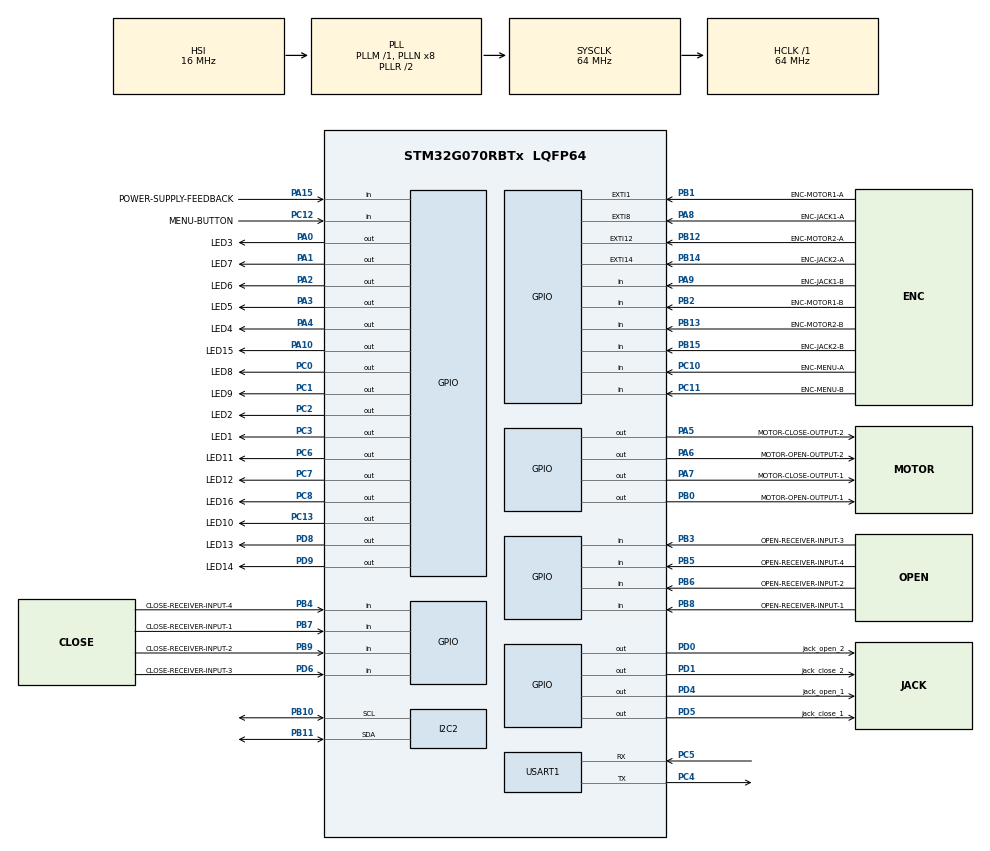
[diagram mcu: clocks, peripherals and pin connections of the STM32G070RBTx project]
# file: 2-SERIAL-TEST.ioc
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Dma.Request0=USART1_TX
Dma.USART1_TX.0.Direction=DMA_MEMORY_TO_PERIPH
Dma.USART1_TX.0.EventEnable=DISABLE
Dma.USART1_TX.0.Instance=DMA1_Channel1
Dma.USART1_TX.0.MemDataAlignment=DMA_MDATAALIGN_BYTE
Dma.USART1_TX.0.MemInc=DMA_MINC_ENABLE
Dma.USART1_TX.0.Mode=DMA_NORMAL
Dma.USART1_TX.0.PeriphDataAlignment=DMA_PDATAALIGN_BYTE
Dma.USART1_TX.0.PeriphInc=DMA_PINC_DISABLE
Dma.USART1_TX.0.Polarity=HAL_DMAMUX_REQ_GEN_RISING
Dma.USART1_TX.0.Priority=DMA_PRIORITY_HIGH
Dma.USART1_TX.0.RequestNumber=1
Dma.USART1_TX.0.SignalID=NONE
Dma.USART1_TX.0.SyncEnable=DISABLE
Dma.USART1_TX.0.SyncPolarity=HAL_DMAMUX_SYNC_NO_EVENT
Dma.USART1_TX.0.SyncRequestNumber=1
Dma.USART1_TX.0.SyncSignalID=NONE
I2C2.Timing=0x10B17DB5
Mcu.Family=STM32G0
Mcu.Name=STM32G070RBTx
Mcu.Package=LQFP64
NVIC.DMA1_Channel1_IRQn=true\:0\:0\:false\:false\:true\:false\:true\:true
NVIC.EXTI0_1_IRQn=true\:0\:0\:false\:false\:true\:true\:true\:true
NVIC.EXTI4_15_IRQn=true\:0\:0\:false\:false\:true\:true\:true\:true
NVIC.USART1_IRQn=true\:0\:0\:false\:false\:true\:true\:true\:true
PA0.GPIO_Label=LED3
PA0.Signal=GPIO_Output
PA1.GPIO_Label=LED7
PA1.Signal=GPIO_Output
PA10.GPIO_Label=LED15
PA10.Signal=GPIO_Output
PA13.Mode=Serial_Wire
PA13.Signal=SYS_SWDIO
PA14-BOOT0.Mode=Serial_Wire
PA14-BOOT0.Signal=SYS_SWCLK
PA15.GPIO_Label=POWER-SUPPLY-FEEDBACK
PA15.GPIO_PuPd=GPIO_NOPULL
PA15.Signal=GPIO_Input
PA2.GPIO_Label=LED6
PA2.Signal=GPIO_Output
PA3.GPIO_Label=LED5
PA3.Signal=GPIO_Output
PA4.GPIO_Label=LED4
PA4.Signal=GPIO_Output
PA5.GPIO_Label=MOTOR-CLOSE-OUTPUT-2
PA5.Signal=GPIO_Output
PA6.GPIO_Label=MOTOR-OPEN-OUTPUT-2
PA6.Signal=GPIO_Output
PA7.GPIO_Label=MOTOR-CLOSE-OUTPUT-1
PA7.Signal=GPIO_Output
PA8.GPIO_Label=ENC-JACK1-A
PA8.Signal=GPXTI8
PA9.GPIO_Label=ENC-JACK1-B
PA9.Signal=GPIO_Input
PB0.GPIO_Label=MOTOR-OPEN-OUTPUT-1
PB0.Signal=GPIO_Output
PB1.GPIO_Label=ENC-MOTOR1-A
PB1.Signal=GPXTI1
PB10.Mode=I2C
PB10.Signal=I2C2_SCL
PB11.Mode=I2C
PB11.Signal=I2C2_SDA
PB12.GPIO_Label=ENC-MOTOR2-A
PB12.Signal=GPXTI12
PB13.GPIO_Label=ENC-MOTOR2-B
PB13.Signal=GPIO_Input
PB14.GPIO_Label=ENC-JACK2-A
PB14.Signal=GPXTI14
PB15.GPIO_Label=ENC-JACK2-B
PB15.Signal=GPIO_Input
PB2.GPIO_Label=ENC-MOTOR1-B
PB2.Signal=GPIO_Input
PB3.GPIO_Label=OPEN-RECEIVER-INPUT-3
PB3.GPIO_PuPd=GPIO_PULLDOWN
PB3.Signal=GPIO_Input
PB4.GPIO_Label=CLOSE-RECEIVER-INPUT-4
PB4.GPIO_PuPd=GPIO_PULLDOWN
PB4.Signal=GPIO_Input
PB5.GPIO_Label=OPEN-RECEIVER-INPUT-4
PB5.GPIO_PuPd=GPIO_PULLDOWN
PB5.Signal=GPIO_Input
PB6.GPIO_Label=OPEN-RECEIVER-INPUT-2
PB6.GPIO_PuPd=GPIO_PULLDOWN
PB6.Signal=GPIO_Input
PB7.GPIO_Label=CLOSE-RECEIVER-INPUT-1
PB7.GPIO_PuPd=GPIO_PULLDOWN
PB7.Signal=GPIO_Input
PB8.GPIO_Label=OPEN-RECEIVER-INPUT-1
PB8.GPIO_PuPd=GPIO_PULLDOWN
PB8.Signal=GPIO_Input
PB9.GPIO_Label=CLOSE-RECEIVER-INPUT-2
PB9.GPIO_PuPd=GPIO_PULLDOWN
PB9.Signal=GPIO_Input
PC0.GPIO_Label=LED8
PC0.Signal=GPIO_Output
PC1.GPIO_Label=LED9
PC1.Signal=GPIO_Output
PC10.GPIO_Label=ENC-MENU-A
PC10.GPIO_PuPd=GPIO_PULLDOWN
PC10.Signal=GPIO_Input
PC11.GPIO_Label=ENC-MENU-B
PC11.Signal=GPIO_Input
PC12.GPIO_Label=MENU-BUTTON
PC12.Signal=GPIO_Input
PC13.GPIO_Label=LED10
PC13.Signal=GPIO_Output
PC2.GPIO_Label=LED2
PC2.Signal=GPIO_Output
PC3.GPIO_Label=LED1
PC3.Signal=GPIO_Output
PC4.Mode=Asynchronous
PC4.Signal=USART1_TX
PC5.Mode=Asynchronous
PC5.Signal=USART1_RX
PC6.GPIO_Label=LED11
PC6.Signal=GPIO_Output
PC7.GPIO_Label=LED12
PC7.Signal=GPIO_Output
PC8.GPIO_Label=LED16
PC8.Signal=GPIO_Output
PD0.GPIO_Label=jack_open_2
PD0.Signal=GPIO_Output
PD1.GPIO_Label=jack_close_2
PD1.Signal=GPIO_Output
PD4.GPIO_Label=jack_open_1
PD4.Signal=GPIO_Output
PD5.GPIO_Label=jack_close_1
PD5.Signal=GPIO_Output
PD6.GPIO_Label=CLOSE-RECEIVER-INPUT-3
PD6.Signal=GPIO_Input
PD8.GPIO_Label=LED13
PD8.Signal=GPIO_Output
PD9.GPIO_Label=LED14
PD9.Signal=GPIO_Output
PF0-OSC_IN\ (PF0).Mode=HSE-External-Oscillator
PF0-OSC_IN\ (PF0).Signal=RCC_OSC_IN
PF1-OSC_OUT\ (PF1).Mode=HSE-External-Oscillator
PF1-OSC_OUT\ (PF1).Signal=RCC_OSC_OUT
ProjectManager.HeapSize=0x200
ProjectManager.StackSize=0x400
ProjectManager.TargetToolchain=MDK-ARM V5.32
RCC.ADCFreq_Value=64000000
RCC.AHBFreq_Value=64000000
RCC.CortexFreq_Value=64000000
RCC.EXTERNAL_CLOCK_VALUE=48000
RCC.HCLKFreq_Value=64000000
RCC.HSE_VALUE=8000000
RCC.HSI_VALUE=16000000
RCC.LSE_VALUE=32768
RCC.SYSCLKFreq_VALUE=64000000
RCC.SYSCLKSource=RCC_SYSCLKSOURCE_PLLCLK
RCC.VCOOutputFreq_Value=128000000
USART1.VirtualMode-Asynchronous=VM_ASYNC
board=custom

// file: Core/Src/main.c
/* USER CODE BEGIN Header */
/**
  ******************************************************************************
  * @file           : main.c
  * @brief          : Main program body
  ******************************************************************************
  * @attention
  *
  * Copyright (c) 2026 STMicroelectronics.
  * All rights reserved.
  *
  * This software is licensed under terms that can be found in the LICENSE file
  * in the root directory of this software component.
  * If no LICENSE file comes with this software, it is provided AS-IS.
  *
  ******************************************************************************
  */
/* USER CODE END Header */
#include "main.h"

/* USER CODE BEGIN Includes */
#include "MyApp.h"
#include "STM32PrintfUART.h"
/* USER CODE END Includes */

I2C_HandleTypeDef hi2c2;

UART_HandleTypeDef huart1;
DMA_HandleTypeDef hdma_usart1_tx;

void SystemClock_Config(void);
static void MX_GPIO_Init(void);
static void MX_DMA_Init(void);
static void MX_I2C2_Init(void);
static void MX_USART1_UART_Init(void);

int main(void)
{

  /* MCU Configuration--------------------------------------------------------*/

  /* Reset of all peripherals, Initializes the Flash interface and the Systick. */
  HAL_Init();

  /* Configure the system clock */
  SystemClock_Config();

  /* Initialize all configured peripherals */
  MX_GPIO_Init();
  MX_DMA_Init();
  MX_I2C2_Init();
  MX_USART1_UART_Init();

  /* Infinite loop */
  /* USER CODE BEGIN WHILE */
  while (1)
  {

		My_App();
		UART_TX_Task();
    /* USER CODE END WHILE */

  }
}

void SystemClock_Config(void)
{
  RCC_OscInitTypeDef RCC_OscInitStruct = {0};
  RCC_ClkInitTypeDef RCC_ClkInitStruct = {0};

  /** Configure the main internal regulator output voltage
  */
  HAL_PWREx_ControlVoltageScaling(PWR_REGULATOR_VOLTAGE_SCALE1);

  /** Initializes the RCC Oscillators according to the specified parameters
  * in the RCC_OscInitTypeDef structure.
  */
  RCC_OscInitStruct.OscillatorType = RCC_OSCILLATORTYPE_HSI;
  RCC_OscInitStruct.HSIState = RCC_HSI_ON;
  RCC_OscInitStruct.HSIDiv = RCC_HSI_DIV1;
  RCC_OscInitStruct.HSICalibrationValue = RCC_HSICALIBRATION_DEFAULT;
  RCC_OscInitStruct.PLL.PLLState = RCC_PLL_ON;
  RCC_OscInitStruct.PLL.PLLSource = RCC_PLLSOURCE_HSI;
  RCC_OscInitStruct.PLL.PLLM = RCC_PLLM_DIV1;
  RCC_OscInitStruct.PLL.PLLN = 8;
  RCC_OscInitStruct.PLL.PLLP = RCC_PLLP_DIV2;
  RCC_OscInitStruct.PLL.PLLR = RCC_PLLR_DIV2;
  if (HAL_RCC_OscConfig(&RCC_OscInitStruct) != HAL_OK)
  {
    Error_Handler();
  }

  /** Initializes the CPU, AHB and APB buses clocks
  */
  RCC_ClkInitStruct.ClockType = RCC_CLOCKTYPE_HCLK|RCC_CLOCKTYPE_SYSCLK
                              |RCC_CLOCKTYPE_PCLK1;
  RCC_ClkInitStruct.SYSCLKSource = RCC_SYSCLKSOURCE_PLLCLK;
  RCC_ClkInitStruct.AHBCLKDivider = RCC_SYSCLK_DIV1;
  RCC_ClkInitStruct.APB1CLKDivider = RCC_HCLK_DIV1;

  if (HAL_RCC_ClockConfig(&RCC_ClkInitStruct, FLASH_LATENCY_2) != HAL_OK)
  {
    Error_Handler();
  }
}

static void MX_I2C2_Init(void)
{

  hi2c2.Instance = I2C2;
  hi2c2.Init.Timing = 0x10B17DB5;
  hi2c2.Init.OwnAddress1 = 0;
  hi2c2.Init.AddressingMode = I2C_ADDRESSINGMODE_7BIT;
  hi2c2.Init.DualAddressMode = I2C_DUALADDRESS_DISABLE;
  hi2c2.Init.OwnAddress2 = 0;
  hi2c2.Init.OwnAddress2Masks = I2C_OA2_NOMASK;
  hi2c2.Init.GeneralCallMode = I2C_GENERALCALL_DISABLE;
  hi2c2.Init.NoStretchMode = I2C_NOSTRETCH_DISABLE;
  if (HAL_I2C_Init(&hi2c2) != HAL_OK)
  {
    Error_Handler();
  }

  /** Configure Analogue filter
  */
  if (HAL_I2CEx_ConfigAnalogFilter(&hi2c2, I2C_ANALOGFILTER_ENABLE) != HAL_OK)
  {
    Error_Handler();
  }

  /** Configure Digital filter
  */
  if (HAL_I2CEx_ConfigDigitalFilter(&hi2c2, 0) != HAL_OK)
  {
    Error_Handler();
  }

}

static void MX_USART1_UART_Init(void)
{

  huart1.Instance = USART1;
  huart1.Init.BaudRate = 115200;
  huart1.Init.WordLength = UART_WORDLENGTH_8B;
  huart1.Init.StopBits = UART_STOPBITS_1;
  huart1.Init.Parity = UART_PARITY_NONE;
  huart1.Init.Mode = UART_MODE_TX_RX;
  huart1.Init.HwFlowCtl = UART_HWCONTROL_NONE;
  huart1.Init.OverSampling = UART_OVERSAMPLING_16;
  huart1.Init.OneBitSampling = UART_ONE_BIT_SAMPLE_DISABLE;
  huart1.Init.ClockPrescaler = UART_PRESCALER_DIV1;
  huart1.AdvancedInit.AdvFeatureInit = UART_ADVFEATURE_NO_INIT;
  if (HAL_UART_Init(&huart1) != HAL_OK)
  {
    Error_Handler();
  }
  if (HAL_UARTEx_SetTxFifoThreshold(&huart1, UART_TXFIFO_THRESHOLD_1_8) != HAL_OK)
  {
    Error_Handler();
  }
  if (HAL_UARTEx_SetRxFifoThreshold(&huart1, UART_RXFIFO_THRESHOLD_1_8) != HAL_OK)
  {
    Error_Handler();
  }
  if (HAL_UARTEx_DisableFifoMode(&huart1) != HAL_OK)
  {
    Error_Handler();
  }

}

static void MX_DMA_Init(void)
{

  /* DMA controller clock enable */
  __HAL_RCC_DMA1_CLK_ENABLE();

  /* DMA interrupt init */
  /* DMA1_Channel1_IRQn interrupt configuration */
  HAL_NVIC_SetPriority(DMA1_Channel1_IRQn, 0, 0);
  HAL_NVIC_EnableIRQ(DMA1_Channel1_IRQn);

}

static void MX_GPIO_Init(void)
{
  GPIO_InitTypeDef GPIO_InitStruct = {0};

  /* GPIO Ports Clock Enable */
  __HAL_RCC_GPIOC_CLK_ENABLE();
  __HAL_RCC_GPIOF_CLK_ENABLE();
  __HAL_RCC_GPIOA_CLK_ENABLE();
  __HAL_RCC_GPIOB_CLK_ENABLE();
  __HAL_RCC_GPIOD_CLK_ENABLE();

  /*Configure GPIO pin Output Level */
  HAL_GPIO_WritePin(GPIOC, LED10_Pin|LED8_Pin|LED9_Pin|LED2_Pin
                          |LED1_Pin|LED11_Pin|LED12_Pin|LED16_Pin, GPIO_PIN_RESET);

  /*Configure GPIO pin Output Level */
  HAL_GPIO_WritePin(GPIOA, LED3_Pin|LED7_Pin|LED6_Pin|LED5_Pin
                          |LED4_Pin|MOTOR_CLOSE_OUTPUT_2_Pin|MOTOR_OPEN_OUTPUT_2_Pin|MOTOR_CLOSE_OUTPUT_1_Pin
                          |LED15_Pin, GPIO_PIN_RESET);

  /*Configure GPIO pin Output Level */
  HAL_GPIO_WritePin(MOTOR_OPEN_OUTPUT_1_GPIO_Port, MOTOR_OPEN_OUTPUT_1_Pin, GPIO_PIN_RESET);

  /*Configure GPIO pin Output Level */
  HAL_GPIO_WritePin(GPIOD, LED13_Pin|LED14_Pin|jack_open_2_Pin|jack_close_2_Pin
                          |jack_open_1_Pin|jack_close_1_Pin, GPIO_PIN_RESET);

  /*Configure GPIO pins : ENC_MENU_B_Pin MENU_BUTTON_Pin */
  GPIO_InitStruct.Pin = ENC_MENU_B_Pin|MENU_BUTTON_Pin;
  GPIO_InitStruct.Mode = GPIO_MODE_INPUT;
  GPIO_InitStruct.Pull = GPIO_NOPULL;
  HAL_GPIO_Init(GPIOC, &GPIO_InitStruct);

  /*Configure GPIO pins : LED10_Pin LED8_Pin LED9_Pin LED2_Pin
                           LED1_Pin LED11_Pin LED12_Pin LED16_Pin */
  GPIO_InitStruct.Pin = LED10_Pin|LED8_Pin|LED9_Pin|LED2_Pin
                          |LED1_Pin|LED11_Pin|LED12_Pin|LED16_Pin;
  GPIO_InitStruct.Mode = GPIO_MODE_OUTPUT_PP;
  GPIO_InitStruct.Pull = GPIO_NOPULL;
  GPIO_InitStruct.Speed = GPIO_SPEED_FREQ_LOW;
  HAL_GPIO_Init(GPIOC, &GPIO_InitStruct);

  /*Configure GPIO pins : PC14 PC15 PC9 */
  GPIO_InitStruct.Pin = GPIO_PIN_14|GPIO_PIN_15|GPIO_PIN_9;
  GPIO_InitStruct.Mode = GPIO_MODE_ANALOG;
  GPIO_InitStruct.Pull = GPIO_NOPULL;
  HAL_GPIO_Init(GPIOC, &GPIO_InitStruct);

  /*Configure GPIO pins : LED3_Pin LED7_Pin LED6_Pin LED5_Pin
                           LED4_Pin MOTOR_CLOSE_OUTPUT_2_Pin MOTOR_OPEN_OUTPUT_2_Pin MOTOR_CLOSE_OUTPUT_1_Pin
                           LED15_Pin */
  GPIO_InitStruct.Pin = LED3_Pin|LED7_Pin|LED6_Pin|LED5_Pin
                          |LED4_Pin|MOTOR_CLOSE_OUTPUT_2_Pin|MOTOR_OPEN_OUTPUT_2_Pin|MOTOR_CLOSE_OUTPUT_1_Pin
                          |LED15_Pin;
  GPIO_InitStruct.Mode = GPIO_MODE_OUTPUT_PP;
  GPIO_InitStruct.Pull = GPIO_NOPULL;
  GPIO_InitStruct.Speed = GPIO_SPEED_FREQ_LOW;
  HAL_GPIO_Init(GPIOA, &GPIO_InitStruct);

  /*Configure GPIO pin : MOTOR_OPEN_OUTPUT_1_Pin */
  GPIO_InitStruct.Pin = MOTOR_OPEN_OUTPUT_1_Pin;
  GPIO_InitStruct.Mode = GPIO_MODE_OUTPUT_PP;
  GPIO_InitStruct.Pull = GPIO_NOPULL;
  GPIO_InitStruct.Speed = GPIO_SPEED_FREQ_LOW;
  HAL_GPIO_Init(MOTOR_OPEN_OUTPUT_1_GPIO_Port, &GPIO_InitStruct);

  /*Configure GPIO pins : ENC_MOTOR1_A_Pin ENC_MOTOR2_A_Pin ENC_JACK2_A_Pin */
  GPIO_InitStruct.Pin = ENC_MOTOR1_A_Pin|ENC_MOTOR2_A_Pin|ENC_JACK2_A_Pin;
  GPIO_InitStruct.Mode = GPIO_MODE_IT_RISING;
  GPIO_InitStruct.Pull = GPIO_NOPULL;
  HAL_GPIO_Init(GPIOB, &GPIO_InitStruct);

  /*Configure GPIO pins : ENC_MOTOR1_B_Pin ENC_MOTOR2_B_Pin ENC_JACK2_B_Pin */
  GPIO_InitStruct.Pin = ENC_MOTOR1_B_Pin|ENC_MOTOR2_B_Pin|ENC_JACK2_B_Pin;
  GPIO_InitStruct.Mode = GPIO_MODE_INPUT;
  GPIO_InitStruct.Pull = GPIO_NOPULL;
  HAL_GPIO_Init(GPIOB, &GPIO_InitStruct);

  /*Configure GPIO pin : ENC_JACK1_A_Pin */
  GPIO_InitStruct.Pin = ENC_JACK1_A_Pin;
  GPIO_InitStruct.Mode = GPIO_MODE_IT_RISING;
  GPIO_InitStruct.Pull = GPIO_NOPULL;
  HAL_GPIO_Init(ENC_JACK1_A_GPIO_Port, &GPIO_InitStruct);

  /*Configure GPIO pins : ENC_JACK1_B_Pin POWER_SUPPLY_FEEDBACK_Pin */
  GPIO_InitStruct.Pin = ENC_JACK1_B_Pin|POWER_SUPPLY_FEEDBACK_Pin;
  GPIO_InitStruct.Mode = GPIO_MODE_INPUT;
  GPIO_InitStruct.Pull = GPIO_NOPULL;
  HAL_GPIO_Init(GPIOA, &GPIO_InitStruct);

  /*Configure GPIO pins : LED13_Pin LED14_Pin jack_open_2_Pin jack_close_2_Pin
                           jack_open_1_Pin jack_close_1_Pin */
  GPIO_InitStruct.Pin = LED13_Pin|LED14_Pin|jack_open_2_Pin|jack_close_2_Pin
                          |jack_open_1_Pin|jack_close_1_Pin;
  GPIO_InitStruct.Mode = GPIO_MODE_OUTPUT_PP;
  GPIO_InitStruct.Pull = GPIO_NOPULL;
  GPIO_InitStruct.Speed = GPIO_SPEED_FREQ_LOW;
  HAL_GPIO_Init(GPIOD, &GPIO_InitStruct);

  /*Configure GPIO pins : PA11 PA12 */
  GPIO_InitStruct.Pin = GPIO_PIN_11|GPIO_PIN_12;
  GPIO_InitStruct.Mode = GPIO_MODE_ANALOG;
  GPIO_InitStruct.Pull = GPIO_NOPULL;
  HAL_GPIO_Init(GPIOA, &GPIO_InitStruct);

  /*Configure GPIO pins : PD2 PD3 */
  GPIO_InitStruct.Pin = GPIO_PIN_2|GPIO_PIN_3;
  GPIO_InitStruct.Mode = GPIO_MODE_ANALOG;
  GPIO_InitStruct.Pull = GPIO_NOPULL;
  HAL_GPIO_Init(GPIOD, &GPIO_InitStruct);

  /*Configure GPIO pin : CLOSE_RECEIVER_INPUT_3_Pin */
  GPIO_InitStruct.Pin = CLOSE_RECEIVER_INPUT_3_Pin;
  GPIO_InitStruct.Mode = GPIO_MODE_INPUT;
  GPIO_InitStruct.Pull = GPIO_NOPULL;
  HAL_GPIO_Init(CLOSE_RECEIVER_INPUT_3_GPIO_Port, &GPIO_InitStruct);

  /*Configure GPIO pins : OPEN_RECEIVER_INPUT_3_Pin CLOSE_RECEIVER_INPUT_4_Pin OPEN_RECEIVER_INPUT_4_Pin OPEN_RECEIVER_INPUT_2_Pin
                           CLOSE_RECEIVER_INPUT_1_Pin OPEN_RECEIVER_INPUT_1_Pin CLOSE_RECEIVER_INPUT_2_Pin */
  GPIO_InitStruct.Pin = OPEN_RECEIVER_INPUT_3_Pin|CLOSE_RECEIVER_INPUT_4_Pin|OPEN_RECEIVER_INPUT_4_Pin|OPEN_RECEIVER_INPUT_2_Pin
                          |CLOSE_RECEIVER_INPUT_1_Pin|OPEN_RECEIVER_INPUT_1_Pin|CLOSE_RECEIVER_INPUT_2_Pin;
  GPIO_InitStruct.Mode = GPIO_MODE_INPUT;
  GPIO_InitStruct.Pull = GPIO_PULLDOWN;
  HAL_GPIO_Init(GPIOB, &GPIO_InitStruct);

  /*Configure GPIO pin : ENC_MENU_A_Pin */
  GPIO_InitStruct.Pin = ENC_MENU_A_Pin;
  GPIO_InitStruct.Mode = GPIO_MODE_INPUT;
  GPIO_InitStruct.Pull = GPIO_PULLDOWN;
  HAL_GPIO_Init(ENC_MENU_A_GPIO_Port, &GPIO_InitStruct);

  /* EXTI interrupt init*/
  HAL_NVIC_SetPriority(EXTI0_1_IRQn, 0, 0);
  HAL_NVIC_EnableIRQ(EXTI0_1_IRQn);

  HAL_NVIC_SetPriority(EXTI4_15_IRQn, 0, 0);
  HAL_NVIC_EnableIRQ(EXTI4_15_IRQn);

}

void Error_Handler(void)
{
  __disable_irq();
  while (1)
  {
  }
}
